AUTOSAR XML (schema 4-0-3)
package /ComponentTypes
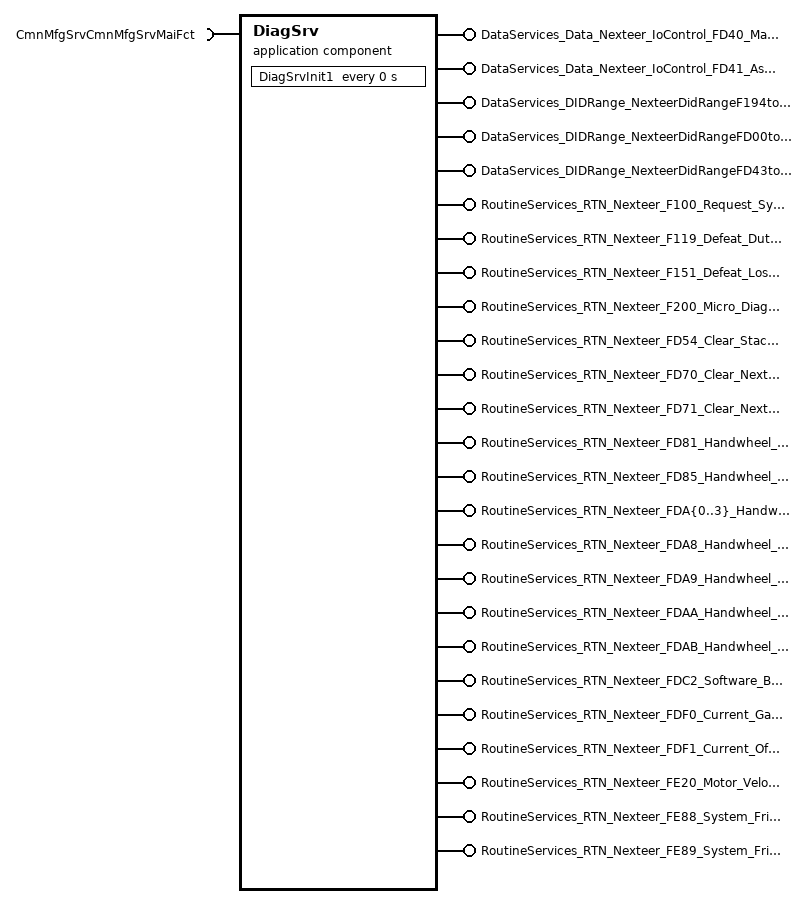
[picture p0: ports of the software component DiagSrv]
  application sw component type DiagSrv
    28 x provide port:
      DataServices_Data_Nexteer_IoControl_FD40_Manual_Torque_Command: provided-interface=DataServices_Data_Nexteer_IoControl_FD40_Manual_Torque_Command
        provided-com-specs:
          operation=ReadData, queue-length=1
          operation=ReadDataLength, queue-length=1
          operation=ReturnControlToECU, queue-length=1
          operation=ShortTermAdjustment, queue-length=1
      DataServices_Data_Nexteer_IoControl_FD41_Assist_Linear_Gain: provided-interface=DataServices_Data_Nexteer_IoControl_FD41_Assist_Linear_Gain
        provided-com-specs:
          operation=ReadData, queue-length=1
          operation=ReadDataLength, queue-length=1
          operation=ReturnControlToECU, queue-length=1
          operation=ShortTermAdjustment, queue-length=1
      DataServices_DIDRange_NexteerDidRangeF194toF1FF: provided-com-specs=[{operation=ReadDidData, queue-length=1}, {operation=WriteDidData, queue-length=1}], provided-interface=DataServices_DIDRange_NexteerDidRangeF194toF1FF
      DataServices_DIDRange_NexteerDidRangeFD00toFD39: provided-com-specs=[{operation=ReadDidData, queue-length=1}, {operation=WriteDidData, queue-length=1}], provided-interface=DataServices_DIDRange_NexteerDidRangeFD00toFD39
      DataServices_DIDRange_NexteerDidRangeFD43toFEFF: provided-com-specs=[{operation=ReadDidData, queue-length=1}, {operation=WriteDidData, queue-length=1}], provided-interface=DataServices_DIDRange_NexteerDidRangeFD43toFEFF
      RoutineServices_RTN_Nexteer_F100_Request_System_State_Enable: provided-interface=RoutineServices_RTN_Nexteer_F100_Request_System_State_Enable
        provided-com-specs:
          operation=RequestResults, queue-length=1
          operation=Start, queue-length=1
          operation=Stop, queue-length=1
      RoutineServices_RTN_Nexteer_F119_Defeat_Duty_Cycle_Thermal_Protection: provided-interface=RoutineServices_RTN_Nexteer_F119_Defeat_Duty_Cycle_Thermal_Protection
        provided-com-specs:
          operation=RequestResults, queue-length=1
          operation=Start, queue-length=1
          operation=Stop, queue-length=1
      RoutineServices_RTN_Nexteer_F151_Defeat_Loss_of_Assist_Scale: provided-interface=RoutineServices_RTN_Nexteer_F151_Defeat_Loss_of_Assist_Scale
        provided-com-specs:
          operation=RequestResults, queue-length=1
          operation=Start, queue-length=1
          operation=Stop, queue-length=1
      RoutineServices_RTN_Nexteer_F200_Micro_Diagnostic_Fault_Injection: server-com-spec{operation=Start, queue-length=1}, provided-interface=RoutineServices_RTN_Nexteer_F200_Micro_Diagnostic_Fault_Injection
      RoutineServices_RTN_Nexteer_FD54_Clear_Stack_Measurement_Result: server-com-spec{operation=Start, queue-length=1}, provided-interface=RoutineServices_RTN_Nexteer_FD54_Clear_Stack_Measurement_Result
      RoutineServices_RTN_Nexteer_FD70_Clear_Nexteer_Trouble_Codes: server-com-spec{operation=Start, queue-length=1}, provided-interface=RoutineServices_RTN_Nexteer_FD70_Clear_Nexteer_Trouble_Codes
      RoutineServices_RTN_Nexteer_FD71_Clear_Nexteer_Snapshot_Data_Start: server-com-spec{operation=Start, queue-length=1}, provided-interface=RoutineServices_RTN_Nexteer_FD71_Clear_Nexteer_Snapshot_Data_Start
      RoutineServices_RTN_Nexteer_FD81_Handwheel_Angle_1_Auto_Trim: server-com-spec{operation=Start, queue-length=1}, provided-interface=RoutineServices_RTN_Nexteer_FD81_Handwheel_Angle_1_Auto_Trim
      RoutineServices_RTN_Nexteer_FD85_Handwheel_Angle_1_Clear_Trim: server-com-spec{operation=Start, queue-length=1}, provided-interface=RoutineServices_RTN_Nexteer_FD85_Handwheel_Angle_1_Clear_Trim
      RoutineServices_RTN_Nexteer_FDA{0..3}_Handwheel_Torque_Sensor_{0..3}_Auto_Trim: server-com-spec{operation=Start, queue-length=1}, provided-interface=RoutineServices_RTN_Nexteer_FDA{0..3}_Handwheel_Torque_Sensor_{0..3}_Auto_Trim
      RoutineServices_RTN_Nexteer_FDA8_Handwheel_Torque_Sensor_0_Clear_Trim: server-com-spec{operation=Start, queue-length=1}, provided-interface=RoutineServices_RTN_Nexteer_FDA8_Handwheel_Torque_Sensor_0_Clear_Trim
      RoutineServices_RTN_Nexteer_FDA9_Handwheel_Torque_Sensor_1_Clear_Trim: server-com-spec{operation=Start, queue-length=1}, provided-interface=RoutineServices_RTN_Nexteer_FDA9_Handwheel_Torque_Sensor_1_Clear_Trim
      RoutineServices_RTN_Nexteer_FDAA_Handwheel_Torque_Sensor_2_Clear_Trim: server-com-spec{operation=Start, queue-length=1}, provided-interface=RoutineServices_RTN_Nexteer_FDAA_Handwheel_Torque_Sensor_2_Clear_Trim
      RoutineServices_RTN_Nexteer_FDAB_Handwheel_Torque_Sensor_3_Clear_Trim: server-com-spec{operation=Start, queue-length=1}, provided-interface=RoutineServices_RTN_Nexteer_FDAB_Handwheel_Torque_Sensor_3_Clear_Trim
      RoutineServices_RTN_Nexteer_FDC2_Software_Based_Motor_Calibration: provided-interface=RoutineServices_RTN_Nexteer_FDC2_Software_Based_Motor_Calibration
        provided-com-specs:
          operation=RequestResults, queue-length=1
          operation=Start, queue-length=1
          operation=Stop, queue-length=1
      RoutineServices_RTN_Nexteer_FDF0_Current_Gain_Auto_Trim: provided-com-specs=[{operation=RequestResults, queue-length=1}, {operation=Start, queue-length=1}], provided-interface=RoutineServices_RTN_Nexteer_FDF0_Current_Gain_Auto_Trim
      RoutineServices_RTN_Nexteer_FDF1_Current_Offset_Auto_Trim: provided-com-specs=[{operation=RequestResults, queue-length=1}, {operation=Start, queue-length=1}], provided-interface=RoutineServices_RTN_Nexteer_FDF1_Current_Offset_Auto_Trim
      RoutineServices_RTN_Nexteer_FE20_Motor_Velocity_Control: provided-com-specs=[{operation=Start, queue-length=1}, {operation=Stop, queue-length=1}], provided-interface=RoutineServices_RTN_Nexteer_FE20_Motor_Velocity_Control
      RoutineServices_RTN_Nexteer_FE88_System_Friction_Learning_Clear: server-com-spec{operation=Start, queue-length=1}, provided-interface=RoutineServices_RTN_Nexteer_FE88_System_Friction_Learning_Clear
      RoutineServices_RTN_Nexteer_FE89_System_Friction_Learning_Initialize: server-com-spec{operation=Start, queue-length=1}, provided-interface=RoutineServices_RTN_Nexteer_FE89_System_Friction_Learning_Initialize
    require port CmnMfgSrvCmnMfgSrvMaiFct: client-com-spec=Oper, required-interface=CmnMfgSrvCmnMfgSrvMaiFct
    behavior DiagSrv_InternalBehavior
      8 x operation invoked event:
        OIT_DataServices_Data_Nexteer_IoControl_FD40_Manual_Torque_Command_ReadData_DataServices_Data_Nexteer_IoControl_FD40_Man210944B3: start-on-event=DataServices_Data_Nexteer_IoControl_FD40_Manual_Torque_Command_ReadData, operation=DataServices_Data_Nexteer_IoControl_FD40_Manual_Torque_Command.ReadData
        OIT_DataServices_Data_Nexteer_IoControl_FD40_Manual_Torque_Command_ReadDataLength_DataServices_Data_Nexteer_IoControl_FD1FF29175: start-on-event=DataServices_Data_Nexteer_IoControl_FD40_Manual_Torque_Command_ReadDataLength, operation=DataServices_Data_Nexteer_IoControl_FD40_Manual_Torque_Command.ReadDataLength
        OIT_DataServices_Data_Nexteer_IoControl_FD40_Manual_Torque_Command_ReturnControlToECU_DataServices_Data_Nexteer_IoControAD21BCB8: start-on-event=DataServices_Data_Nexteer_IoControl_FD40_Manual_Torque_Command_ReturnControlToECU, operation=DataServices_Data_Nexteer_IoControl_FD40_Manual_Torque_Command.ReturnControlToECU
        OIT_DataServices_Data_Nexteer_IoControl_FD40_Manual_Torque_Command_ShortTermAdjustment_DataServices_Data_Nexteer_IoContr8658917E: start-on-event=DataServices_Data_Nexteer_IoControl_FD40_Manual_Torque_Command_ShortTermAdjustment, operation=DataServices_Data_Nexteer_IoControl_FD40_Manual_Torque_Command.ShortTermAdjustment
        OIT_DataServices_Data_Nexteer_IoControl_FD41_Assist_Linear_Gain_ReadData_DataServices_Data_Nexteer_IoControl_FD41_Assist3CB13D0D: start-on-event=DataServices_Data_Nexteer_IoControl_FD41_Assist_Linear_Gain_ReadData, operation=DataServices_Data_Nexteer_IoControl_FD41_Assist_Linear_Gain.ReadData
        OIT_DataServices_Data_Nexteer_IoControl_FD41_Assist_Linear_Gain_ReadDataLength_DataServices_Data_Nexteer_IoControl_FD41_9109A317: start-on-event=DataServices_Data_Nexteer_IoControl_FD41_Assist_Linear_Gain_ReadDataLength, operation=DataServices_Data_Nexteer_IoControl_FD41_Assist_Linear_Gain.ReadDataLength
        OIT_DataServices_Data_Nexteer_IoControl_FD41_Assist_Linear_Gain_ReturnControlToECU_DataServices_Data_Nexteer_IoControl_F683089E9: start-on-event=DataServices_Data_Nexteer_IoControl_FD41_Assist_Linear_Gain_ReturnControlToECU, operation=DataServices_Data_Nexteer_IoControl_FD41_Assist_Linear_Gain.ReturnControlToECU
        OIT_DataServices_Data_Nexteer_IoControl_FD41_Assist_Linear_Gain_ShortTermAdjustment_DataServices_Data_Nexteer_IoControl_8C975677: start-on-event=DataServices_Data_Nexteer_IoControl_FD41_Assist_Linear_Gain_ShortTermAdjustment, operation=DataServices_Data_Nexteer_IoControl_FD41_Assist_Linear_Gain.ShortTermAdjustment
      timing event DiagSrv_InitEvent: start-on-event=DiagSrvInit1, period=0
      40 x operation invoked event:
        OIT_NexteerDidRead_DataServices_DIDRange_NexteerDidRangeF194toF1FF_ReadDidData: start-on-event=NexteerDidRead, operation=DataServices_DIDRange_NexteerDidRangeF194toF1FF.ReadDidData
        OIT_NexteerDidRead_DataServices_DIDRange_NexteerDidRangeFD00toFD39_ReadDidData: start-on-event=NexteerDidRead, operation=DataServices_DIDRange_NexteerDidRangeFD00toFD39.ReadDidData
        OIT_NexteerDidRead_DataServices_DIDRange_NexteerDidRangeFD43toFEFF_ReadDidData: start-on-event=NexteerDidRead, operation=DataServices_DIDRange_NexteerDidRangeFD43toFEFF.ReadDidData
        OIT_NexteerDidWrite_DataServices_DIDRange_NexteerDidRangeF194toF1FF_WriteDidData: start-on-event=NexteerDidWrite, operation=DataServices_DIDRange_NexteerDidRangeF194toF1FF.WriteDidData
        OIT_NexteerDidWrite_DataServices_DIDRange_NexteerDidRangeFD00toFD39_WriteDidData: start-on-event=NexteerDidWrite, operation=DataServices_DIDRange_NexteerDidRangeFD00toFD39.WriteDidData
        OIT_NexteerDidWrite_DataServices_DIDRange_NexteerDidRangeFD43toFEFF_WriteDidData: start-on-event=NexteerDidWrite, operation=DataServices_DIDRange_NexteerDidRangeFD43toFEFF.WriteDidData
        OIT_RoutineServices_RTN_Nexteer_F100_Request_System_State_Enable_RequestResults_RoutineServices_RTN_Nexteer_F100_Request2AEEFE44: start-on-event=RoutineServices_RTN_Nexteer_F100_Request_System_State_Enable_RequestResults, operation=RoutineServices_RTN_Nexteer_F100_Request_System_State_Enable.RequestResults
        OIT_RoutineServices_RTN_Nexteer_F100_Request_System_State_Enable_Start_RoutineServices_RTN_Nexteer_F100_Request_System_SC229A0CD: start-on-event=RoutineServices_RTN_Nexteer_F100_Request_System_State_Enable_Start, operation=RoutineServices_RTN_Nexteer_F100_Request_System_State_Enable.Start
        OIT_RoutineServices_RTN_Nexteer_F100_Request_System_State_Enable_Stop_RoutineServices_RTN_Nexteer_F100_Request_System_St5F164609: start-on-event=RoutineServices_RTN_Nexteer_F100_Request_System_State_Enable_Stop, operation=RoutineServices_RTN_Nexteer_F100_Request_System_State_Enable.Stop
        OIT_RoutineServices_RTN_Nexteer_F119_Defeat_Duty_Cycle_Thermal_Protection_RequestResults_RoutineServices_RTN_Nexteer_F11BC4C480D: start-on-event=RoutineServices_RTN_Nexteer_F119_Defeat_Duty_Cycle_Thermal_Protection_RequestResults, operation=RoutineServices_RTN_Nexteer_F119_Defeat_Duty_Cycle_Thermal_Protection.RequestResults
        OIT_RoutineServices_RTN_Nexteer_F119_Defeat_Duty_Cycle_Thermal_Protection_Start_RoutineServices_RTN_Nexteer_F119_Defeat_D4BFB237: start-on-event=RoutineServices_RTN_Nexteer_F119_Defeat_Duty_Cycle_Thermal_Protection_Start, operation=RoutineServices_RTN_Nexteer_F119_Defeat_Duty_Cycle_Thermal_Protection.Start
        OIT_RoutineServices_RTN_Nexteer_F119_Defeat_Duty_Cycle_Thermal_Protection_Stop_RoutineServices_RTN_Nexteer_F119_Defeat_DC8BD7286: start-on-event=RoutineServices_RTN_Nexteer_F119_Defeat_Duty_Cycle_Thermal_Protection_Stop, operation=RoutineServices_RTN_Nexteer_F119_Defeat_Duty_Cycle_Thermal_Protection.Stop
        OIT_RoutineServices_RTN_Nexteer_F151_Defeat_Loss_of_Assist_Scale_RequestResults_RoutineServices_RTN_Nexteer_F151_Defeat_C345D9B8: start-on-event=RoutineServices_RTN_Nexteer_F151_Defeat_Loss_of_Assist_Scale_RequestResults, operation=RoutineServices_RTN_Nexteer_F151_Defeat_Loss_of_Assist_Scale.RequestResults
        OIT_RoutineServices_RTN_Nexteer_F151_Defeat_Loss_of_Assist_Scale_Start_RoutineServices_RTN_Nexteer_F151_Defeat_Loss_of_AF8401154: start-on-event=RoutineServices_RTN_Nexteer_F151_Defeat_Loss_of_Assist_Scale_Start, operation=RoutineServices_RTN_Nexteer_F151_Defeat_Loss_of_Assist_Scale.Start
        OIT_RoutineServices_RTN_Nexteer_F151_Defeat_Loss_of_Assist_Scale_Stop_RoutineServices_RTN_Nexteer_F151_Defeat_Loss_of_As18E021E7: start-on-event=RoutineServices_RTN_Nexteer_F151_Defeat_Loss_of_Assist_Scale_Stop, operation=RoutineServices_RTN_Nexteer_F151_Defeat_Loss_of_Assist_Scale.Stop
        OIT_RoutineServices_RTN_Nexteer_F200_Micro_Diagnostic_Fault_Injection_Start_RoutineServices_RTN_Nexteer_F200_Micro_DiagnFEA1B893: start-on-event=RoutineServices_RTN_Nexteer_F200_Micro_Diagnostic_Fault_Injection_Start, operation=RoutineServices_RTN_Nexteer_F200_Micro_Diagnostic_Fault_Injection.Start
        OIT_RoutineServices_RTN_Nexteer_FD54_Clear_Stack_Measurement_Result_Start_RoutineServices_RTN_Nexteer_FD54_Clear_Stack_MB0E87B97: start-on-event=RoutineServices_RTN_Nexteer_FD54_Clear_Stack_Measurement_Result_Start, operation=RoutineServices_RTN_Nexteer_FD54_Clear_Stack_Measurement_Result.Start
        OIT_RoutineServices_RTN_Nexteer_FD70_Clear_Nexteer_Trouble_Codes_Start_RoutineServices_RTN_Nexteer_FD70_Clear_Nexteer_Tr3A584688: start-on-event=RoutineServices_RTN_Nexteer_FD70_Clear_Nexteer_Trouble_Codes_Start, operation=RoutineServices_RTN_Nexteer_FD70_Clear_Nexteer_Trouble_Codes.Start
        OIT_RoutineServices_RTN_Nexteer_FD71_Clear_Nexteer_Snapshot_Data_Start_Start_RoutineServices_RTN_Nexteer_FD71_Clear_NextDFE5DDE6: start-on-event=RoutineServices_RTN_Nexteer_FD71_Clear_Nexteer_Snapshot_Data_Start_Start, operation=RoutineServices_RTN_Nexteer_FD71_Clear_Nexteer_Snapshot_Data_Start.Start
        OIT_RoutineServices_RTN_Nexteer_FD81_Handwheel_Angle_1_Auto_Trim_Start_RoutineServices_RTN_Nexteer_FD81_Handwheel_Angle_BB3A7822: start-on-event=RoutineServices_RTN_Nexteer_FD81_Handwheel_Angle_1_Auto_Trim_Start, operation=RoutineServices_RTN_Nexteer_FD81_Handwheel_Angle_1_Auto_Trim.Start
        OIT_RoutineServices_RTN_Nexteer_FD85_Handwheel_Angle_1_Clear_Trim_Start_RoutineServices_RTN_Nexteer_FD85_Handwheel_Angle20DF0BE1: start-on-event=RoutineServices_RTN_Nexteer_FD85_Handwheel_Angle_1_Clear_Trim_Start, operation=RoutineServices_RTN_Nexteer_FD85_Handwheel_Angle_1_Clear_Trim.Start
        OIT_RoutineServices_RTN_Nexteer_FDA0_Handwheel_Torque_Sensor_0_Auto_Trim_Start_RoutineServices_RTN_Nexteer_FDA0_HandwheeFD82ADE5: start-on-event=RoutineServices_RTN_Nexteer_FDA0_Handwheel_Torque_Sensor_0_Auto_Trim_Start, operation=RoutineServices_RTN_Nexteer_FDA0_Handwheel_Torque_Sensor_0_Auto_Trim.Start
        OIT_RoutineServices_RTN_Nexteer_FDA1_Handwheel_Torque_Sensor_1_Auto_Trim_Start_RoutineServices_RTN_Nexteer_FDA1_Handwhee1F5B0F7D: start-on-event=RoutineServices_RTN_Nexteer_FDA1_Handwheel_Torque_Sensor_1_Auto_Trim_Start, operation=RoutineServices_RTN_Nexteer_FDA1_Handwheel_Torque_Sensor_1_Auto_Trim.Start
        OIT_RoutineServices_RTN_Nexteer_FDA2_Handwheel_Torque_Sensor_2_Auto_Trim_Start_RoutineServices_RTN_Nexteer_FDA2_HandwheeE340EE94: start-on-event=RoutineServices_RTN_Nexteer_FDA2_Handwheel_Torque_Sensor_2_Auto_Trim_Start, operation=RoutineServices_RTN_Nexteer_FDA2_Handwheel_Torque_Sensor_2_Auto_Trim.Start
        OIT_RoutineServices_RTN_Nexteer_FDA3_Handwheel_Torque_Sensor_3_Auto_Trim_Start_RoutineServices_RTN_Nexteer_FDA3_Handwhee01994C0C: start-on-event=RoutineServices_RTN_Nexteer_FDA3_Handwheel_Torque_Sensor_3_Auto_Trim_Start, operation=RoutineServices_RTN_Nexteer_FDA3_Handwheel_Torque_Sensor_3_Auto_Trim.Start
        OIT_RoutineServices_RTN_Nexteer_FDA8_Handwheel_Torque_Sensor_0_Clear_Trim_Start_RoutineServices_RTN_Nexteer_FDA8_Handwhe2EE9F31D: start-on-event=RoutineServices_RTN_Nexteer_FDA8_Handwheel_Torque_Sensor_0_Clear_Trim_Start, operation=RoutineServices_RTN_Nexteer_FDA8_Handwheel_Torque_Sensor_0_Clear_Trim.Start
        OIT_RoutineServices_RTN_Nexteer_FDA9_Handwheel_Torque_Sensor_1_Clear_Trim_Start_RoutineServices_RTN_Nexteer_FDA9_Handwhe1EA7F585: start-on-event=RoutineServices_RTN_Nexteer_FDA9_Handwheel_Torque_Sensor_1_Clear_Trim_Start, operation=RoutineServices_RTN_Nexteer_FDA9_Handwheel_Torque_Sensor_1_Clear_Trim.Start
        OIT_RoutineServices_RTN_Nexteer_FDAA_Handwheel_Torque_Sensor_2_Clear_Trim_Start_RoutineServices_RTN_Nexteer_FDAA_Handwhe4660D0EA: start-on-event=RoutineServices_RTN_Nexteer_FDAA_Handwheel_Torque_Sensor_2_Clear_Trim_Start, operation=RoutineServices_RTN_Nexteer_FDAA_Handwheel_Torque_Sensor_2_Clear_Trim.Start
        OIT_RoutineServices_RTN_Nexteer_FDAB_Handwheel_Torque_Sensor_3_Clear_Trim_Start_RoutineServices_RTN_Nexteer_FDAB_HandwheDB127D75: start-on-event=RoutineServices_RTN_Nexteer_FDAB_Handwheel_Torque_Sensor_3_Clear_Trim_Start, operation=RoutineServices_RTN_Nexteer_FDAB_Handwheel_Torque_Sensor_3_Clear_Trim.Start
        OIT_RoutineServices_RTN_Nexteer_FDC2_Software_Based_Motor_Calibration_RequestResults_RoutineServices_RTN_Nexteer_FDC2_So6D5B3025: start-on-event=RoutineServices_RTN_Nexteer_FDC2_Software_Based_Motor_Calibration_RequestResults, operation=RoutineServices_RTN_Nexteer_FDC2_Software_Based_Motor_Calibration.RequestResults
        OIT_RoutineServices_RTN_Nexteer_FDC2_Software_Based_Motor_Calibration_Start_RoutineServices_RTN_Nexteer_FDC2_Software_BaABCB1F9B: start-on-event=RoutineServices_RTN_Nexteer_FDC2_Software_Based_Motor_Calibration_Start, operation=RoutineServices_RTN_Nexteer_FDC2_Software_Based_Motor_Calibration.Start
        OIT_RoutineServices_RTN_Nexteer_FDC2_Software_Based_Motor_Calibration_Stop_RoutineServices_RTN_Nexteer_FDC2_Software_Bas14410A5F: start-on-event=RoutineServices_RTN_Nexteer_FDC2_Software_Based_Motor_Calibration_Stop, operation=RoutineServices_RTN_Nexteer_FDC2_Software_Based_Motor_Calibration.Stop
        OIT_RoutineServices_RTN_Nexteer_FDF0_Current_Gain_Auto_Trim_RequestResults_RoutineServices_RTN_Nexteer_FDF0_Current_GainC7FFE7CF: start-on-event=RoutineServices_RTN_Nexteer_FDF0_Current_Gain_Auto_Trim_RequestResults, operation=RoutineServices_RTN_Nexteer_FDF0_Current_Gain_Auto_Trim.RequestResults
        OIT_RoutineServices_RTN_Nexteer_FDF0_Current_Gain_Auto_Trim_Start_RoutineServices_RTN_Nexteer_FDF0_Current_Gain_Auto_Trim_Start: start-on-event=RoutineServices_RTN_Nexteer_FDF0_Current_Gain_Auto_Trim_Start, operation=RoutineServices_RTN_Nexteer_FDF0_Current_Gain_Auto_Trim.Start
        OIT_RoutineServices_RTN_Nexteer_FDF1_Current_Offset_Auto_Trim_RequestResults_RoutineServices_RTN_Nexteer_FDF1_Current_OfB67F7FA1: start-on-event=RoutineServices_RTN_Nexteer_FDF1_Current_Offset_Auto_Trim_RequestResults, operation=RoutineServices_RTN_Nexteer_FDF1_Current_Offset_Auto_Trim.RequestResults
        OIT_RoutineServices_RTN_Nexteer_FDF1_Current_Offset_Auto_Trim_Start_RoutineServices_RTN_Nexteer_FDF1_Current_Offset_Auto1B2E03C2: start-on-event=RoutineServices_RTN_Nexteer_FDF1_Current_Offset_Auto_Trim_Start, operation=RoutineServices_RTN_Nexteer_FDF1_Current_Offset_Auto_Trim.Start
        OIT_RoutineServices_RTN_Nexteer_FE20_Motor_Velocity_Control_Start_RoutineServices_RTN_Nexteer_FE20_Motor_Velocity_Control_Start: start-on-event=RoutineServices_RTN_Nexteer_FE20_Motor_Velocity_Control_Start, operation=RoutineServices_RTN_Nexteer_FE20_Motor_Velocity_Control.Start
        OIT_RoutineServices_RTN_Nexteer_FE20_Motor_Velocity_Control_Stop_RoutineServices_RTN_Nexteer_FE20_Motor_Velocity_Control_Stop: start-on-event=RoutineServices_RTN_Nexteer_FE20_Motor_Velocity_Control_Stop, operation=RoutineServices_RTN_Nexteer_FE20_Motor_Velocity_Control.Stop
        OIT_RoutineServices_RTN_Nexteer_FE88_System_Friction_Learning_Clear_Start_RoutineServices_RTN_Nexteer_FE88_System_FrictiE50801CE: start-on-event=RoutineServices_RTN_Nexteer_FE88_System_Friction_Learning_Clear_Start, operation=RoutineServices_RTN_Nexteer_FE88_System_Friction_Learning_Clear.Start
        OIT_RoutineServices_RTN_Nexteer_FE89_System_Friction_Learning_Initialize_Start_RoutineServices_RTN_Nexteer_FE89_System_FE11C4A2F: start-on-event=RoutineServices_RTN_Nexteer_FE89_System_Friction_Learning_Initialize_Start, operation=RoutineServices_RTN_Nexteer_FE89_System_Friction_Learning_Initialize.Start
      port-api-options:
        enable-take-address=false, indirect-api=false, port=CmnMfgSrvCmnMfgSrvMaiFct
        enable-take-address=false, indirect-api=false, port=DataServices_Data_Nexteer_IoControl_FD40_Manual_Torque_Command
        enable-take-address=false, indirect-api=false, port=DataServices_Data_Nexteer_IoControl_FD41_Assist_Linear_Gain
        enable-take-address=false, indirect-api=false, port=DataServices_DIDRange_NexteerDidRangeF194toF1FF
        enable-take-address=false, indirect-api=false, port=DataServices_DIDRange_NexteerDidRangeFD00toFD39
        enable-take-address=false, indirect-api=false, port=DataServices_DIDRange_NexteerDidRangeFD43toFEFF
        enable-take-address=false, indirect-api=false, port=RoutineServices_RTN_Nexteer_F100_Request_System_State_Enable
        enable-take-address=false, indirect-api=false, port=RoutineServices_RTN_Nexteer_F119_Defeat_Duty_Cycle_Thermal_Protection
        enable-take-address=false, indirect-api=false, port=RoutineServices_RTN_Nexteer_F151_Defeat_Loss_of_Assist_Scale
        enable-take-address=false, indirect-api=false, port=RoutineServices_RTN_Nexteer_F200_Micro_Diagnostic_Fault_Injection
        enable-take-address=false, indirect-api=false, port=RoutineServices_RTN_Nexteer_FD54_Clear_Stack_Measurement_Result
        enable-take-address=false, indirect-api=false, port=RoutineServices_RTN_Nexteer_FD70_Clear_Nexteer_Trouble_Codes
        enable-take-address=false, indirect-api=false, port=RoutineServices_RTN_Nexteer_FD71_Clear_Nexteer_Snapshot_Data_Start
        enable-take-address=false, indirect-api=false, port=RoutineServices_RTN_Nexteer_FD81_Handwheel_Angle_1_Auto_Trim
        enable-take-address=false, indirect-api=false, port=RoutineServices_RTN_Nexteer_FD85_Handwheel_Angle_1_Clear_Trim
        enable-take-address=false, indirect-api=false, port=RoutineServices_RTN_Nexteer_FDA{0..3}_Handwheel_Torque_Sensor_{0..3}_Auto_Trim
        enable-take-address=false, indirect-api=false, port=RoutineServices_RTN_Nexteer_FDA8_Handwheel_Torque_Sensor_0_Clear_Trim
        enable-take-address=false, indirect-api=false, port=RoutineServices_RTN_Nexteer_FDA9_Handwheel_Torque_Sensor_1_Clear_Trim
        enable-take-address=false, indirect-api=false, port=RoutineServices_RTN_Nexteer_FDAA_Handwheel_Torque_Sensor_2_Clear_Trim
        enable-take-address=false, indirect-api=false, port=RoutineServices_RTN_Nexteer_FDAB_Handwheel_Torque_Sensor_3_Clear_Trim
        enable-take-address=false, indirect-api=false, port=RoutineServices_RTN_Nexteer_FDC2_Software_Based_Motor_Calibration
        enable-take-address=false, indirect-api=false, port=RoutineServices_RTN_Nexteer_FDF0_Current_Gain_Auto_Trim
        enable-take-address=false, indirect-api=false, port=RoutineServices_RTN_Nexteer_FDF1_Current_Offset_Auto_Trim
        enable-take-address=false, indirect-api=false, port=RoutineServices_RTN_Nexteer_FE20_Motor_Velocity_Control
        enable-take-address=false, indirect-api=false, port=RoutineServices_RTN_Nexteer_FE88_System_Friction_Learning_Clear
        enable-take-address=false, indirect-api=false, port=RoutineServices_RTN_Nexteer_FE89_System_Friction_Learning_Initialize
      45 x runnable:
        DataServices_Data_Nexteer_IoControl_FD40_Manual_Torque_Command_ReadData
        DataServices_Data_Nexteer_IoControl_FD40_Manual_Torque_Command_ReadDataLength
        DataServices_Data_Nexteer_IoControl_FD40_Manual_Torque_Command_ReturnControlToECU
        DataServices_Data_Nexteer_IoControl_FD40_Manual_Torque_Command_ShortTermAdjustment
        DataServices_Data_Nexteer_IoControl_FD41_Assist_Linear_Gain_ReadData
        DataServices_Data_Nexteer_IoControl_FD41_Assist_Linear_Gain_ReadDataLength
        DataServices_Data_Nexteer_IoControl_FD41_Assist_Linear_Gain_ReturnControlToECU
        DataServices_Data_Nexteer_IoControl_FD41_Assist_Linear_Gain_ShortTermAdjustment
        DiagSrvInit1
          sync call SC_CmnMfgSrvCmnMfgSrvMaiFct_Oper: operation=CmnMfgSrvCmnMfgSrvMaiFct.Oper, timeout=0
        NexteerDidRead
        NexteerDidWrite
        RoutineServices_RTN_Nexteer_F100_Request_System_State_Enable_RequestResults
        RoutineServices_RTN_Nexteer_F100_Request_System_State_Enable_Start
        RoutineServices_RTN_Nexteer_F100_Request_System_State_Enable_Stop
        RoutineServices_RTN_Nexteer_F119_Defeat_Duty_Cycle_Thermal_Protection_RequestResults
        RoutineServices_RTN_Nexteer_F119_Defeat_Duty_Cycle_Thermal_Protection_Start
        RoutineServices_RTN_Nexteer_F119_Defeat_Duty_Cycle_Thermal_Protection_Stop
        RoutineServices_RTN_Nexteer_F151_Defeat_Loss_of_Assist_Scale_RequestResults
        RoutineServices_RTN_Nexteer_F151_Defeat_Loss_of_Assist_Scale_Start
        RoutineServices_RTN_Nexteer_F151_Defeat_Loss_of_Assist_Scale_Stop
        RoutineServices_RTN_Nexteer_F200_Micro_Diagnostic_Fault_Injection_Start
        RoutineServices_RTN_Nexteer_FD54_Clear_Stack_Measurement_Result_Start
        RoutineServices_RTN_Nexteer_FD70_Clear_Nexteer_Trouble_Codes_Start
        RoutineServices_RTN_Nexteer_FD71_Clear_Nexteer_Snapshot_Data_Start_Start
        RoutineServices_RTN_Nexteer_FD81_Handwheel_Angle_1_Auto_Trim_Start
        RoutineServices_RTN_Nexteer_FD85_Handwheel_Angle_1_Clear_Trim_Start
        RoutineServices_RTN_Nexteer_FDA{0..3}_Handwheel_Torque_Sensor_{0..3}_Auto_Trim_Start
        RoutineServices_RTN_Nexteer_FDA8_Handwheel_Torque_Sensor_0_Clear_Trim_Start
        RoutineServices_RTN_Nexteer_FDA9_Handwheel_Torque_Sensor_1_Clear_Trim_Start
        RoutineServices_RTN_Nexteer_FDAA_Handwheel_Torque_Sensor_2_Clear_Trim_Start
        RoutineServices_RTN_Nexteer_FDAB_Handwheel_Torque_Sensor_3_Clear_Trim_Start
        RoutineServices_RTN_Nexteer_FDC2_Software_Based_Motor_Calibration_RequestResults
        RoutineServices_RTN_Nexteer_FDC2_Software_Based_Motor_Calibration_Start
        RoutineServices_RTN_Nexteer_FDC2_Software_Based_Motor_Calibration_Stop
        RoutineServices_RTN_Nexteer_FDF0_Current_Gain_Auto_Trim_RequestResults
        RoutineServices_RTN_Nexteer_FDF0_Current_Gain_Auto_Trim_Start
        RoutineServices_RTN_Nexteer_FDF1_Current_Offset_Auto_Trim_RequestResults
        RoutineServices_RTN_Nexteer_FDF1_Current_Offset_Auto_Trim_Start
        RoutineServices_RTN_Nexteer_FE20_Motor_Velocity_Control_Start
        RoutineServices_RTN_Nexteer_FE20_Motor_Velocity_Control_Stop
        RoutineServices_RTN_Nexteer_FE88_System_Friction_Learning_Clear_Start
        RoutineServices_RTN_Nexteer_FE89_System_Friction_Learning_Initialize_Start
  swc implementation DiagSrv_Implementation: behavior=DiagSrv_InternalBehavior
    code-descriptors:
      code Default: artifact-descriptors=autosar-engineering-object={short-label=Default, category=SWSRC}
